# TC35678 register map
Vendor: Toshiba Electronic Devices and Storage Corporation; File version: 0.1
CPU: CM0 r0p0, little endian, no MPU, no FPU, 4 interrupt priority bits
Registers are 32-bit, read-write, no defined reset value unless marked. A register's access mark holds for its fields unless they carry their own. Offsets are from the block's base; lines under a group give offsets from that group; [hi:lo] are bit positions; {n}, {i} and the like mark numbered series; 'fields as' and 'values as' point back to an identical list; <NAME> marks a mode.

## Memory map
0x40001000 DMAC size 0x200
0x40040240 BluetoothCounter size 0x100
0x40046000 SPI size 0x30 — Serial Peripheral Interface(Master/Slave)
0x4004A100 PWM size 0x400 — Pulse Width Modulation
0x4004C000 Clock size 0x100 — Clock Supply for SPI and PWM
0x4004E000 GPIO size 0x500 — General Purpose Input/Output
0x40055000 PowerManagement size 0x200 — Power Management (GPIO, RTC)

## PWM — Pulse Width Modulation
Base 0x4004A100
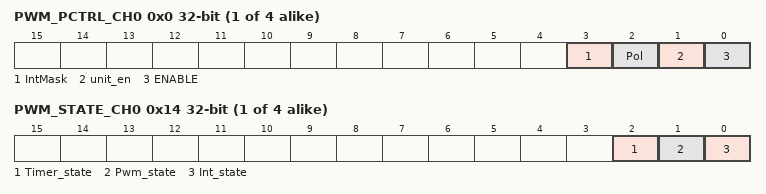
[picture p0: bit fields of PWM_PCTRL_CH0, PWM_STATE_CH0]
{0x0+0x100*i} PWM_PCTRL_CH{i} (i=0..3) — PWM CH{i} enable control
  [3] IntMask — PWM interrupt mask (R/W) 0: Interrupt output enabled 1: Interrupt disabled (default)
  [2] Pol — PWM output polarity control (R/W) 0: Polarity inversion OFF (default) 1: Polarity inversion ON
  [1] unit_en — 1-s timer enable (R/W) 0: Timer OFF (default) 1: Timer ON Please set this off before unit_starvalue is to be changed. When this is off, rhythm settings has no effect.
  [0] ENABLE — PWM channel enable (R/W) 0: Stop (default) 1: Start Please set cycle and duty before this is set to start.
{0x4+0x100*i} PWM_PATTERN_CH{i} (i=0..3) — PWM CH{i} output mask set
  [19:0] Rhythm_Pat — PWM is output during the time this defines. 1 bit corresponds to 50 ms. 0: Output mask ON (No PWM output) 1: Output mask OFF (PWM output) This has no effect when 1-s timer is OFF.
{0x8+0x100*i} PWM_CYCLE_CH{i} (i=0..3) — PWM CH{i} cycle set
  [11:0] cycle — Cycle count register determines the PWM output period. 0 to 4095 (0x000 to 0xFFF)
{0xC+0x100*i} PWM_DUTY_CH{i} (i=0..3) — PWM CH{i} duty set
  [11:0] Duty — Determines the duty ratio. 0 to 4095 (0x000 to 0xFFF) duty ratio = (this value)/(cycle + 1)
{0x10+0x100*i} PWM_UNIT_CH{i} (i=0..3) — PWM CH{i} rhythm counter period set
  [19:0] Unit_startvalue — Counter value setting to count 50 ms 0x0665 for 32.768 kHz (default) 0x9EB0F for 13 MHz Before to change this value, please make sure that PCTRL[1] unit_en = 0, STATE[2] Timer_state = 1, Pwm_state = 1.
{0x14+0x100*i} PWM_STATE_CH{i} (i=0..3) — PWM CH{i} status
  [2] Timer_state — 1-s timer status 0: ON 1: Idle
  [1] Pwm_state — Cycle counter status 0: ON 1: Idle
  [0] Int_state — INT status 0: Not interrupted 1: Interrupted This is cleared when INTClr bit 0 is set to 1.
{0x18+0x100*i} PWM_INTCLR_CH{i} (i=0..2) — PWM CH{i} interrupt clear
  [0] IntClr — PWM interrupt clear register (initial 0, W) Writeing 1 to this register clears the interrupt status.
0x318 PWM_INTCLR_CH3 reset 0x0 — PWM CH3 interrupt clear
  fields as PWM_INTCLR_CH0

## SPI — Serial Peripheral Interface(Master/Slave)
Base 0x40046000
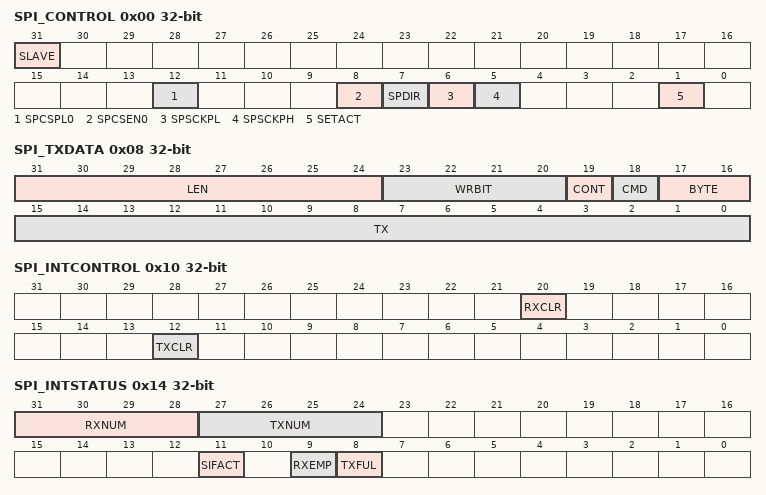
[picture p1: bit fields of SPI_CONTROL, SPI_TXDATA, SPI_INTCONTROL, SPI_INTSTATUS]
0x00 SPI_CONTROL
  [31] SLAVE — Set master/slave mode (R/W) 0: Master mode (default) 1: Slave mode
  [12] SPCSPL0 — Set CS polarity (R/W) 0: Low active (default) 1: High active
  [8] SPCSEN0 — Enable CS (R/W) 0: Disable 1: Enable (default)
  [7] SPDIR — Specify LSB/MSB first (R/W) 0: MSB first (default) 1: LSB first
  [6] SPSCKPL — Specify serial clock polarity (R/W) 0: Sampling at high (default) 1: Sampling at low
  [5] SPSCKPH — Specify serial clock phase (R/W) 0: Sampling at the first edge (default) 1: Sampling at the second edge
  [1] SETACT — Set operation mode (R/W) 0: Configuration mode 1: Active mode (default)
0x04 SPI_TIMINGCONTROL
  [15:8] BASE — Set frequency devisor (R/W) 0: Not allowed 1-255: Allowed f_SPI = 13/(devisor x 2) MHz e.g. when devisor = 1, f_SPI = 6.5 MHz.
0x08 SPI_TXDATA
  [31:24] LEN — Default value is zero. When CMD is write (bit[18] = 0), set TX options (R/W). bit[31:26] Reserved bit[25] SPI DO polarity (0: L, 1: H) bit[24] SPI DO output status (0: keep the last data, 1: output H/L set at bit 25) When CMD is read (bit[18] = 1), set RX data length (R/W). bit[31:24] RX data length (unit is defined at bit[17:16])
  [23:20] WRBIT — Set valid TX bit length (R/W) 0x0: The setting at bit[17:16] is applied (default). 0x1: 1 bit 0x2: 2 bit ... 0xF: 15 bit
  [19] CONT — Set continuous transfer (R/W) 0: Deassert CS per word (default) 1: Keep CS between words
  [18] CMD — Set transfer command (R/W) 0: Write (default) 1: Read
  [17:16] BYTE — Set transfer byte length (R/W) 00: 1 byte (default) 01: 2 bytes 10: 3 bytes (valid for read) 11: 4 bytes (valid for read)
  [15:0] TX — Set TX data (R/W) Default value is zero.
0x0C SPI_RXDATA ro
  [31:0] RX — Get RX data (R) When data is 24 bit length, [31:24] = 0x00 (default). When data is 16 bit length, [31:16] = 0x0000. When data is 8 bit length, [31:8] = 0x000000.
0x10 SPI_INTCONTROL — SPI intrrupt control
  [20] RXCLR — Clear RX FIFO (R/W) 0: Do not clear (default) 1: Clear After claer, this register becomes 0.
  [12] TXCLR — Clear TX FIFO (R/W) 0: Do not clear (default) 1: Clear After claer, this register becomes 0.
0x14 SPI_INTSTATUS — SPI interrupt status
  [31:28] RXNUM ro — Read deta length in RX FIFO (R) 0000: 0 (default) 0001: 1 ... 0111: 7 1000: 8 Others: Don't care
  [27:24] TXNUM ro — Read deta length in TX FIFO (R) 0000: 0 (default) 0001: 1 ... 0111: 7 1000: 8 Others: Don't care
  [11] SIFACT ro — Read the status of serial interface (R) 0: Idle (default) 1: Operating
  [9] RXEMP ro — Read the status of RX FIFO (R) 0: RX FIFO is empty. 1: RX FIFO is not empty.
  [8] TXFUL ro — Read the status of TX FIFO (R) 0: TX FIFO is full. 1: TX FIFO is not full.
0x20 SPI_TIMINGCONTROL2 — SPI timing control
  [17:16] ADDSPLDLY — Add sampling delay of RX data (R/W) 01: 1 clk delay (fixed)
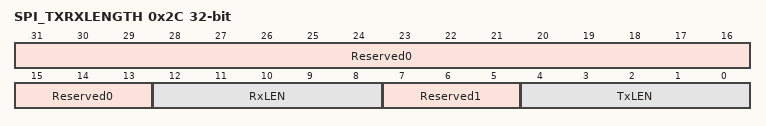
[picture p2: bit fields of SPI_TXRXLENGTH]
0x2C SPI_TXRXLENGTH — SPI Data Langth
  [31:13] Reserved0 — Do not change the values.
  [12:8] RxLEN — Set the length of Rx data length 00-02: Forbidden. 03: 4bit 04: 5bit ... 1E:31bit 1F:32bit
  [7:5] Reserved1 — Do not change the values.
  [4:0] TxLEN — Set the length of Tx data length 00-02: Forbidden 03: 4bit 04: 5bit ... 1E: 31bit 1F: 32bit
